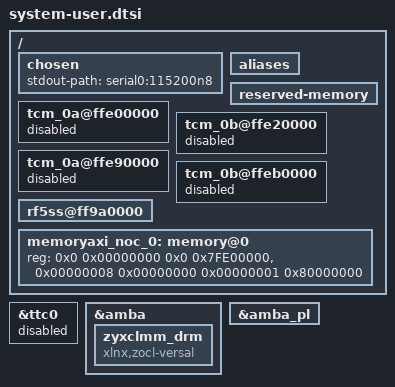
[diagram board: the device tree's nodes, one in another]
/include/ "system-conf.dtsi"
/ {
	chosen {
                stdout-path = "serial0:115200n8";
        };

	aliases {
        	/delete-property/ serial1;
	};

	reserved-memory {
		/delete-node/ rproc@3ed00000;
		/delete-node/ rpu0vdev0vring0@3ed40000;
		/delete-node/ rpu0vdev0vring1@3ed44000;
		/delete-node/ rpu0vdev0buffer@3ed48000;
		/delete-node/ rproc@3ef00000;
		/delete-node/ rpu1vdev0vring0@3ef40000;
		/delete-node/ rpu1vdev0vring1@3ef44000;
		/delete-node/ rpu1vdev0buffer@3ef48000;
	};

	tcm_0a@ffe00000 {
		status = "disabled";
	};

	tcm_0b@ffe20000 {	
		status = "disabled";
	};

	tcm_0a@ffe90000 {
		status = "disabled";
	};

	tcm_0b@ffeb0000 {
		status = "disabled";
	};

	rf5ss@ff9a0000 {
		/delete-node/ r5f_0;
		/delete-node/ r5f_1;
	};

        memoryaxi_noc_0: memory@0 {
                device_type = "memory";
                reg = <0x0 0x00000000 0x0 0x7FE00000>, <0x00000008 0x00000000 0x00000001 0x80000000>;
        };

};

&ttc0 {
	status = "disabled";
};

&amba {
        zyxclmm_drm {
                compatible = "xlnx,zocl-versal";
        };
};

&amba_pl {
        /delete-node/ gpio@a4000000;
	/delete-node/ serial@a4020000;
};
